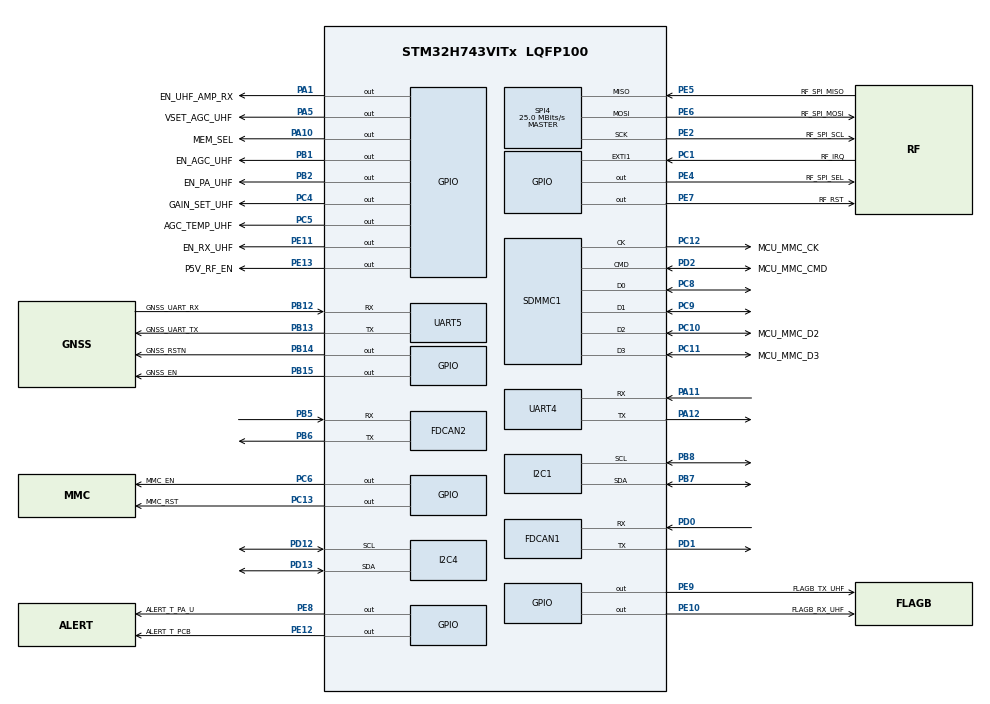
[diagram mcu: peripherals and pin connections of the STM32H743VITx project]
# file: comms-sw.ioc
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Dma.Request0=UART5_RX
Dma.Request1=UART4_TX
Dma.Request2=UART4_RX
Dma.UART4_RX.2.Direction=DMA_PERIPH_TO_MEMORY
Dma.UART4_RX.2.EventEnable=DISABLE
Dma.UART4_RX.2.FIFOMode=DMA_FIFOMODE_DISABLE
Dma.UART4_RX.2.Instance=DMA1_Stream2
Dma.UART4_RX.2.MemDataAlignment=DMA_MDATAALIGN_BYTE
Dma.UART4_RX.2.MemInc=DMA_MINC_ENABLE
Dma.UART4_RX.2.Mode=DMA_NORMAL
Dma.UART4_RX.2.PeriphDataAlignment=DMA_PDATAALIGN_BYTE
Dma.UART4_RX.2.PeriphInc=DMA_PINC_DISABLE
Dma.UART4_RX.2.Polarity=HAL_DMAMUX_REQ_GEN_RISING
Dma.UART4_RX.2.Priority=DMA_PRIORITY_LOW
Dma.UART4_RX.2.RequestNumber=1
Dma.UART4_RX.2.SignalID=NONE
Dma.UART4_RX.2.SyncEnable=DISABLE
Dma.UART4_RX.2.SyncPolarity=HAL_DMAMUX_SYNC_NO_EVENT
Dma.UART4_RX.2.SyncRequestNumber=1
Dma.UART4_RX.2.SyncSignalID=NONE
Dma.UART4_TX.1.Direction=DMA_MEMORY_TO_PERIPH
Dma.UART4_TX.1.EventEnable=DISABLE
Dma.UART4_TX.1.FIFOMode=DMA_FIFOMODE_DISABLE
Dma.UART4_TX.1.Instance=DMA1_Stream1
Dma.UART4_TX.1.MemDataAlignment=DMA_MDATAALIGN_BYTE
Dma.UART4_TX.1.MemInc=DMA_MINC_ENABLE
Dma.UART4_TX.1.Mode=DMA_NORMAL
Dma.UART4_TX.1.PeriphDataAlignment=DMA_PDATAALIGN_BYTE
Dma.UART4_TX.1.PeriphInc=DMA_PINC_DISABLE
Dma.UART4_TX.1.Polarity=HAL_DMAMUX_REQ_GEN_RISING
Dma.UART4_TX.1.Priority=DMA_PRIORITY_LOW
Dma.UART4_TX.1.RequestNumber=1
Dma.UART4_TX.1.SignalID=NONE
Dma.UART4_TX.1.SyncEnable=DISABLE
Dma.UART4_TX.1.SyncPolarity=HAL_DMAMUX_SYNC_NO_EVENT
Dma.UART4_TX.1.SyncRequestNumber=1
Dma.UART4_TX.1.SyncSignalID=NONE
Dma.UART5_RX.0.Direction=DMA_PERIPH_TO_MEMORY
Dma.UART5_RX.0.EventEnable=DISABLE
Dma.UART5_RX.0.FIFOMode=DMA_FIFOMODE_DISABLE
Dma.UART5_RX.0.Instance=DMA1_Stream0
Dma.UART5_RX.0.MemDataAlignment=DMA_MDATAALIGN_BYTE
Dma.UART5_RX.0.MemInc=DMA_MINC_ENABLE
Dma.UART5_RX.0.Mode=DMA_CIRCULAR
Dma.UART5_RX.0.PeriphDataAlignment=DMA_PDATAALIGN_BYTE
Dma.UART5_RX.0.PeriphInc=DMA_PINC_DISABLE
Dma.UART5_RX.0.Polarity=HAL_DMAMUX_REQ_GEN_RISING
Dma.UART5_RX.0.Priority=DMA_PRIORITY_LOW
Dma.UART5_RX.0.RequestNumber=1
Dma.UART5_RX.0.SignalID=NONE
Dma.UART5_RX.0.SyncEnable=DISABLE
Dma.UART5_RX.0.SyncPolarity=HAL_DMAMUX_SYNC_NO_EVENT
Dma.UART5_RX.0.SyncRequestNumber=1
Dma.UART5_RX.0.SyncSignalID=NONE
FDCAN1.CalculateBaudRateNominal=500000
FDCAN1.CalculateTimeBitNominal=2000
FDCAN1.CalculateTimeQuantumNominal=20.0
FDCAN1.DataPrescaler=25
FDCAN1.DataTimeSeg1=2
FDCAN1.ExtFiltersNbr=1
FDCAN1.NominalPrescaler=1
FDCAN1.NominalSyncJumpWidth=13
FDCAN1.NominalTimeSeg1=86
FDCAN1.NominalTimeSeg2=13
FDCAN1.RxFifo0ElmtsNbr=16
FDCAN1.StdFiltersNbr=0
FDCAN1.TxFifoQueueElmtsNbr=16
FDCAN2.CalculateBaudRateNominal=500000
FDCAN2.CalculateTimeBitNominal=2000
FDCAN2.CalculateTimeQuantumNominal=20.0
FDCAN2.DataPrescaler=25
FDCAN2.DataTimeSeg1=2
FDCAN2.ExtFiltersNbr=1
FDCAN2.MessageRAMOffset=586
FDCAN2.NominalPrescaler=1
FDCAN2.NominalSyncJumpWidth=13
FDCAN2.NominalTimeSeg1=86
FDCAN2.NominalTimeSeg2=13
FDCAN2.RxFifo0ElmtsNbr=16
FDCAN2.TxFifoQueueElmtsNbr=16
I2C1.Timing=0x00909FCE
I2C4.Timing=0x00000509
Mcu.Family=STM32H7
Mcu.Name=STM32H743VITx
Mcu.Package=LQFP100
NVIC.DMA1_Stream0_IRQn=true\:5\:0\:true\:false\:true\:false\:true\:true
NVIC.DMA1_Stream1_IRQn=true\:5\:0\:true\:false\:true\:false\:true\:true
NVIC.DMA1_Stream2_IRQn=true\:5\:0\:true\:false\:true\:false\:true\:true
NVIC.EXTI1_IRQn=true\:5\:0\:true\:false\:false\:true\:true\:true
NVIC.FDCAN1_IT0_IRQn=true\:5\:0\:true\:false\:true\:true\:true\:true
NVIC.FDCAN1_IT1_IRQn=true\:5\:0\:true\:false\:true\:true\:true\:true
NVIC.FDCAN2_IT0_IRQn=true\:5\:0\:true\:false\:true\:true\:true\:true
NVIC.FDCAN2_IT1_IRQn=true\:5\:0\:true\:false\:true\:true\:true\:true
NVIC.PriorityGroup=NVIC_PRIORITYGROUP_4
NVIC.SDMMC1_IRQn=true\:5\:0\:true\:false\:true\:true\:true\:true
NVIC.TIM1_UP_IRQn=true\:15\:0\:false\:false\:true\:false\:true\:true
NVIC.TimeBase=TIM1_UP_IRQn
NVIC.TimeBaseIP=TIM1
NVIC.UART4_IRQn=true\:5\:0\:true\:false\:true\:true\:true\:true
NVIC.UART5_IRQn=true\:5\:0\:true\:false\:true\:true\:true\:true
PA1.GPIO_Label=EN_UHF_AMP_RX
PA1.PinAttribute=Free
PA1.Signal=GPIO_Output
PA10.GPIO_Label=MEM_SEL
PA10.Signal=GPIO_Output
PA11.Mode=Asynchronous
PA11.PinAttribute=Free
PA11.Signal=UART4_RX
PA12.Mode=Asynchronous
PA12.PinAttribute=Free
PA12.Signal=UART4_TX
PA13\ (JTMS/SWDIO).Mode=Trace_Asynchronous_SW
PA13\ (JTMS/SWDIO).PinAttribute=Free
PA13\ (JTMS/SWDIO).Signal=DEBUG_JTMS-SWDIO
PA14\ (JTCK/SWCLK).Mode=Trace_Asynchronous_SW
PA14\ (JTCK/SWCLK).PinAttribute=Free
PA14\ (JTCK/SWCLK).Signal=DEBUG_JTCK-SWCLK
PA5.GPIO_Label=VSET_AGC_UHF
PA5.PinAttribute=Free
PA5.Signal=GPIO_Output
PB1.GPIO_Label=EN_AGC_UHF
PB1.PinAttribute=Free
PB1.Signal=GPIO_Output
PB12.GPIO_Label=GNSS_UART_RX
PB12.Mode=Asynchronous
PB12.Signal=UART5_RX
PB13.GPIO_Label=GNSS_UART_TX
PB13.Mode=Asynchronous
PB13.Signal=UART5_TX
PB14.GPIO_Label=GNSS_RSTN
PB14.Signal=GPIO_Output
PB15.GPIO_Label=GNSS_EN
PB15.PinState=GPIO_PIN_SET
PB15.Signal=GPIO_Output
PB2.GPIO_Label=EN_PA_UHF
PB2.PinAttribute=Free
PB2.PinState=GPIO_PIN_SET
PB2.Signal=GPIO_Output
PB3\ (JTDO/TRACESWO).Mode=Trace_Asynchronous_SW
PB3\ (JTDO/TRACESWO).PinAttribute=Free
PB3\ (JTDO/TRACESWO).Signal=DEBUG_JTDO-SWO
PB5.Mode=FDCAN_Activate
PB5.Signal=FDCAN2_RX
PB6.Mode=FDCAN_Activate
PB6.Signal=FDCAN2_TX
PB7.Mode=I2C
PB7.PinAttribute=Free
PB7.Signal=I2C1_SDA
PB8.Mode=I2C
PB8.PinAttribute=Free
PB8.Signal=I2C1_SCL
PC1.GPIO_Label=RF_IRQ
PC1.PinAttribute=Free
PC1.Signal=GPXTI1
PC10.GPIO_Label=MCU_MMC_D2
PC10.GPIO_PuPd=GPIO_PULLUP
PC10.Mode=mmc_4_bits_Wide_bus
PC10.PinAttribute=Free
PC10.Signal=SDMMC1_D2
PC11.GPIO_Label=MCU_MMC_D3
PC11.GPIO_PuPd=GPIO_PULLUP
PC11.Mode=mmc_4_bits_Wide_bus
PC11.PinAttribute=Free
PC11.Signal=SDMMC1_D3
PC12.GPIO_Label=MCU_MMC_CK
PC12.Mode=mmc_4_bits_Wide_bus
PC12.PinAttribute=Free
PC12.Signal=SDMMC1_CK
PC13.GPIO_Label=MMC_RST
PC13.PinAttribute=Free
PC13.PinState=GPIO_PIN_SET
PC13.Signal=GPIO_Output
PC14-OSC32_IN\ (OSC32_IN).Mode=LSE-External-Clock-Source
PC14-OSC32_IN\ (OSC32_IN).PinAttribute=Free
PC14-OSC32_IN\ (OSC32_IN).Signal=RCC_OSC32_IN
PC4.GPIO_Label=GAIN_SET_UHF
PC4.PinAttribute=Free
PC4.Signal=GPIO_Output
PC5.GPIO_Label=AGC_TEMP_UHF
PC5.PinAttribute=Free
PC5.Signal=GPIO_Output
PC6.GPIO_Label=MMC_EN
PC6.GPIO_Speed=GPIO_SPEED_FREQ_VERY_HIGH
PC6.PinState=GPIO_PIN_SET
PC6.Signal=GPIO_Output
PC8.GPIO_PuPd=GPIO_PULLUP
PC8.Mode=mmc_4_bits_Wide_bus
PC8.Signal=SDMMC1_D0
PC9.GPIO_PuPd=GPIO_PULLUP
PC9.Mode=mmc_4_bits_Wide_bus
PC9.Signal=SDMMC1_D1
PD0.Mode=FDCAN_Activate
PD0.Signal=FDCAN1_RX
PD1.Mode=FDCAN_Activate
PD1.Signal=FDCAN1_TX
PD12.Mode=I2C
PD12.Signal=I2C4_SCL
PD13.Mode=I2C
PD13.Signal=I2C4_SDA
PD2.GPIO_Label=MCU_MMC_CMD
PD2.GPIO_PuPd=GPIO_PULLUP
PD2.Mode=mmc_4_bits_Wide_bus
PD2.PinAttribute=Free
PD2.Signal=SDMMC1_CMD
PE10.GPIO_Label=FLAGB_RX_UHF
PE10.Signal=GPIO_Output
PE11.GPIO_Label=EN_RX_UHF
PE11.Signal=GPIO_Output
PE12.GPIO_Label=ALERT_T_PCB
PE12.Signal=GPIO_Output
PE13.GPIO_Label=P5V_RF_EN
PE13.Signal=GPIO_Output
PE2.GPIO_Label=RF_SPI_SCL
PE2.Mode=Full_Duplex_Master
PE2.PinAttribute=Free
PE2.Signal=SPI4_SCK
PE4.GPIO_Label=RF_SPI_SEL
PE4.PinAttribute=Free
PE4.Signal=GPIO_Output
PE5.GPIO_Label=RF_SPI_MISO
PE5.Mode=Full_Duplex_Master
PE5.PinAttribute=Free
PE5.Signal=SPI4_MISO
PE6.GPIO_Label=RF_SPI_MOSI
PE6.Mode=Full_Duplex_Master
PE6.PinAttribute=Free
PE6.Signal=SPI4_MOSI
PE7.GPIO_Label=RF_RST
PE7.PinAttribute=Free
PE7.PinState=GPIO_PIN_RESET
PE7.Signal=GPIO_Output
PE8.GPIO_Label=ALERT_T_PA_U
PE8.PinAttribute=Free
PE8.Signal=GPIO_Output
PE9.GPIO_Label=FLAGB_TX_UHF
PE9.Signal=GPIO_Output
PH0-OSC_IN\ (PH0).Mode=HSE-External-Clock-Source
PH0-OSC_IN\ (PH0).PinAttribute=Free
PH0-OSC_IN\ (PH0).Signal=RCC_OSC_IN
ProjectManager.HeapSize=0x200
ProjectManager.StackSize=0x400
ProjectManager.TargetToolchain=CMake
RCC.ADCFreq_Value=75000000
RCC.APB1Freq_Value=37500000
RCC.APB2Freq_Value=75000000
RCC.APB3Freq_Value=75000000
RCC.APB4Freq_Value=37500000
RCC.CortexFreq_Value=75000000
RCC.D2PPRE1=RCC_APB1_DIV2
RCC.D3PPRE=RCC_APB4_DIV2
RCC.DIVM1=1
RCC.DIVM2=1
RCC.DIVM3=1
RCC.DIVN1=12
RCC.DIVN2=12
RCC.DIVN3=12
RCC.DIVQ2=3
RCC.DIVQ3=1
RCC.DIVR3=75
RCC.FDCANCLockSelection=RCC_FDCANCLKSOURCE_PLL2
RCC.HCLKFreq_Value=75000000
RCC.HSE_VALUE=12000000
RCC.I2C4CLockSelection=RCC_I2C4CLKSOURCE_PLL3
RCC.PLL2FRACN=4096
RCC.PLL3FRACN=4096
RCC.PLLFRACN=4096
RCC.PLLSourceVirtual=RCC_PLLSOURCE_HSE
RCC.SYSCLKFreq_VALUE=75000000
RCC.SYSCLKSource=RCC_SYSCLKSOURCE_PLLCLK
RCC.Spi45ClockSelection=RCC_SPI45CLKSOURCE_PLL2
RCC.USART234578CLockSelection=RCC_USART234578CLKSOURCE_PLL2
RCC.USBFreq_Value=75000000
SDMMC1.ClockDiv=1
SDMMC1.ClockPowerSave=SDMMC_CLOCK_POWER_SAVE_ENABLE
SDMMC1.HardwareFlowControl=SDMMC_HARDWARE_FLOW_CONTROL_ENABLE
SPI4.CalculateBaudRate=25.0 MBits/s
SPI4.DataSize=SPI_DATASIZE_8BIT
SPI4.Direction=SPI_DIRECTION_2LINES
SPI4.Mode=SPI_MODE_MASTER
SPI4.VirtualType=VM_MASTER
UART5.SwapParam=UART_ADVFEATURE_SWAP_ENABLE
VP_CRC_VS_CRC.Mode=CRC_Activate
VP_SYS_VS_tim1.Mode=TIM1
board=custom

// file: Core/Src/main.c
/* USER CODE BEGIN Header */
/**
  ******************************************************************************
  * @file           : main.c
  * @brief          : Main program body
  ******************************************************************************
  * @attention
  *
  * Copyright (c) 2024 STMicroelectronics.
  * All rights reserved.
  *
  * This software is licensed under terms that can be found in the LICENSE file
  * in the root directory of this software component.
  * If no LICENSE file comes with this software, it is provided AS-IS.
  *
  ******************************************************************************
  */
/* USER CODE END Header */
#include "main.h"

CRC_HandleTypeDef hcrc;

FDCAN_HandleTypeDef hfdcan1;
FDCAN_HandleTypeDef hfdcan2;

I2C_HandleTypeDef hi2c1;
I2C_HandleTypeDef hi2c4;

MMC_HandleTypeDef hmmc1;

SPI_HandleTypeDef hspi4;

UART_HandleTypeDef huart4;
UART_HandleTypeDef huart5;
DMA_HandleTypeDef hdma_uart4_tx;
DMA_HandleTypeDef hdma_uart4_rx;
DMA_HandleTypeDef hdma_uart5_rx;

void SystemClock_Config(void);
void PeriphCommonClock_Config(void);
static void MX_GPIO_Init(void);
static void MX_DMA_Init(void);
static void MX_SPI4_Init(void);
static void MX_UART4_Init(void);
static void MX_I2C4_Init(void);
static void MX_I2C1_Init(void);
static void MX_UART5_Init(void);
static void MX_SDMMC1_MMC_Init(void);
static void MX_FDCAN1_Init(void);
static void MX_FDCAN2_Init(void);
static void MX_CRC_Init(void);

/* USER CODE BEGIN 0 */
void app_main(void);
/* USER CODE END 0 */

int main(void)
{

  /* MCU Configuration--------------------------------------------------------*/

  /* Reset of all peripherals, Initializes the Flash interface and the Systick. */
  HAL_Init();

  /* USER CODE BEGIN Init */
    HAL_Delay(1000);
  /* USER CODE END Init */

  /* Configure the system clock */
  SystemClock_Config();

/* Configure the peripherals common clocks */
  PeriphCommonClock_Config();

  /* Initialize all configured peripherals */
  MX_GPIO_Init();
  MX_DMA_Init();
  MX_SPI4_Init();
  MX_UART4_Init();
  MX_I2C4_Init();
  MX_I2C1_Init();
  MX_UART5_Init();
  MX_SDMMC1_MMC_Init();
  MX_FDCAN1_Init();
  MX_FDCAN2_Init();
  MX_CRC_Init();
  /* USER CODE BEGIN 2 */
    app_main();
  /* USER CODE END 2 */

  /* Infinite loop */
  while (1)
  {

  }
}

void SystemClock_Config(void)
{
  RCC_OscInitTypeDef RCC_OscInitStruct = {0};
  RCC_ClkInitTypeDef RCC_ClkInitStruct = {0};

  /** Supply configuration update enable
  */
  HAL_PWREx_ConfigSupply(PWR_LDO_SUPPLY);

  /** Configure the main internal regulator output voltage
  */
  __HAL_PWR_VOLTAGESCALING_CONFIG(PWR_REGULATOR_VOLTAGE_SCALE3);

  while(!__HAL_PWR_GET_FLAG(PWR_FLAG_VOSRDY)) {}

  /** Initializes the RCC Oscillators according to the specified parameters
  * in the RCC_OscInitTypeDef structure.
  */
  RCC_OscInitStruct.OscillatorType = RCC_OSCILLATORTYPE_HSE;
  RCC_OscInitStruct.HSEState = RCC_HSE_BYPASS;
  RCC_OscInitStruct.PLL.PLLState = RCC_PLL_ON;
  RCC_OscInitStruct.PLL.PLLSource = RCC_PLLSOURCE_HSE;
  RCC_OscInitStruct.PLL.PLLM = 1;
  RCC_OscInitStruct.PLL.PLLN = 12;
  RCC_OscInitStruct.PLL.PLLP = 2;
  RCC_OscInitStruct.PLL.PLLQ = 2;
  RCC_OscInitStruct.PLL.PLLR = 2;
  RCC_OscInitStruct.PLL.PLLRGE = RCC_PLL1VCIRANGE_3;
  RCC_OscInitStruct.PLL.PLLVCOSEL = RCC_PLL1VCOMEDIUM;
  RCC_OscInitStruct.PLL.PLLFRACN = 4096;
  if (HAL_RCC_OscConfig(&RCC_OscInitStruct) != HAL_OK)
  {
    Error_Handler();
  }

  /** Initializes the CPU, AHB and APB buses clocks
  */
  RCC_ClkInitStruct.ClockType = RCC_CLOCKTYPE_HCLK|RCC_CLOCKTYPE_SYSCLK
                              |RCC_CLOCKTYPE_PCLK1|RCC_CLOCKTYPE_PCLK2
                              |RCC_CLOCKTYPE_D3PCLK1|RCC_CLOCKTYPE_D1PCLK1;
  RCC_ClkInitStruct.SYSCLKSource = RCC_SYSCLKSOURCE_PLLCLK;
  RCC_ClkInitStruct.SYSCLKDivider = RCC_SYSCLK_DIV1;
  RCC_ClkInitStruct.AHBCLKDivider = RCC_HCLK_DIV1;
  RCC_ClkInitStruct.APB3CLKDivider = RCC_APB3_DIV1;
  RCC_ClkInitStruct.APB1CLKDivider = RCC_APB1_DIV2;
  RCC_ClkInitStruct.APB2CLKDivider = RCC_APB2_DIV1;
  RCC_ClkInitStruct.APB4CLKDivider = RCC_APB4_DIV2;

  if (HAL_RCC_ClockConfig(&RCC_ClkInitStruct, FLASH_LATENCY_1) != HAL_OK)
  {
    Error_Handler();
  }
}

void PeriphCommonClock_Config(void)
{
  RCC_PeriphCLKInitTypeDef PeriphClkInitStruct = {0};

  /** Initializes the peripherals clock
  */
  PeriphClkInitStruct.PeriphClockSelection = RCC_PERIPHCLK_SPI4|RCC_PERIPHCLK_UART5
                              |RCC_PERIPHCLK_FDCAN|RCC_PERIPHCLK_UART4;
  PeriphClkInitStruct.PLL2.PLL2M = 1;
  PeriphClkInitStruct.PLL2.PLL2N = 12;
  PeriphClkInitStruct.PLL2.PLL2P = 2;
  PeriphClkInitStruct.PLL2.PLL2Q = 3;
  PeriphClkInitStruct.PLL2.PLL2R = 2;
  PeriphClkInitStruct.PLL2.PLL2RGE = RCC_PLL2VCIRANGE_3;
  PeriphClkInitStruct.PLL2.PLL2VCOSEL = RCC_PLL2VCOMEDIUM;
  PeriphClkInitStruct.PLL2.PLL2FRACN = 4096;
  PeriphClkInitStruct.Spi45ClockSelection = RCC_SPI45CLKSOURCE_PLL2;
  PeriphClkInitStruct.FdcanClockSelection = RCC_FDCANCLKSOURCE_PLL2;
  PeriphClkInitStruct.Usart234578ClockSelection = RCC_USART234578CLKSOURCE_PLL2;
  if (HAL_RCCEx_PeriphCLKConfig(&PeriphClkInitStruct) != HAL_OK)
  {
    Error_Handler();
  }
}

static void MX_CRC_Init(void)
{

  hcrc.Instance = CRC;
  hcrc.Init.DefaultPolynomialUse = DEFAULT_POLYNOMIAL_ENABLE;
  hcrc.Init.DefaultInitValueUse = DEFAULT_INIT_VALUE_ENABLE;
  hcrc.Init.InputDataInversionMode = CRC_INPUTDATA_INVERSION_NONE;
  hcrc.Init.OutputDataInversionMode = CRC_OUTPUTDATA_INVERSION_DISABLE;
  hcrc.InputDataFormat = CRC_INPUTDATA_FORMAT_BYTES;
  if (HAL_CRC_Init(&hcrc) != HAL_OK)
  {
    Error_Handler();
  }

}

static void MX_FDCAN1_Init(void)
{

  hfdcan1.Instance = FDCAN1;
  hfdcan1.Init.FrameFormat = FDCAN_FRAME_CLASSIC;
  hfdcan1.Init.Mode = FDCAN_MODE_NORMAL;
  hfdcan1.Init.AutoRetransmission = DISABLE;
  hfdcan1.Init.TransmitPause = DISABLE;
  hfdcan1.Init.ProtocolException = DISABLE;
  hfdcan1.Init.NominalPrescaler = 1;
  hfdcan1.Init.NominalSyncJumpWidth = 13;
  hfdcan1.Init.NominalTimeSeg1 = 86;
  hfdcan1.Init.NominalTimeSeg2 = 13;
  hfdcan1.Init.DataPrescaler = 25;
  hfdcan1.Init.DataSyncJumpWidth = 1;
  hfdcan1.Init.DataTimeSeg1 = 2;
  hfdcan1.Init.DataTimeSeg2 = 1;
  hfdcan1.Init.MessageRAMOffset = 0;
  hfdcan1.Init.StdFiltersNbr = 0;
  hfdcan1.Init.ExtFiltersNbr = 1;
  hfdcan1.Init.RxFifo0ElmtsNbr = 16;
  hfdcan1.Init.RxFifo0ElmtSize = FDCAN_DATA_BYTES_8;
  hfdcan1.Init.RxFifo1ElmtsNbr = 0;
  hfdcan1.Init.RxFifo1ElmtSize = FDCAN_DATA_BYTES_8;
  hfdcan1.Init.RxBuffersNbr = 0;
  hfdcan1.Init.RxBufferSize = FDCAN_DATA_BYTES_8;
  hfdcan1.Init.TxEventsNbr = 0;
  hfdcan1.Init.TxBuffersNbr = 0;
  hfdcan1.Init.TxFifoQueueElmtsNbr = 16;
  hfdcan1.Init.TxFifoQueueMode = FDCAN_TX_FIFO_OPERATION;
  hfdcan1.Init.TxElmtSize = FDCAN_DATA_BYTES_8;
  if (HAL_FDCAN_Init(&hfdcan1) != HAL_OK)
  {
    Error_Handler();
  }

}

static void MX_FDCAN2_Init(void)
{

  hfdcan2.Instance = FDCAN2;
  hfdcan2.Init.FrameFormat = FDCAN_FRAME_CLASSIC;
  hfdcan2.Init.Mode = FDCAN_MODE_NORMAL;
  hfdcan2.Init.AutoRetransmission = DISABLE;
  hfdcan2.Init.TransmitPause = DISABLE;
  hfdcan2.Init.ProtocolException = DISABLE;
  hfdcan2.Init.NominalPrescaler = 1;
  hfdcan2.Init.NominalSyncJumpWidth = 13;
  hfdcan2.Init.NominalTimeSeg1 = 86;
  hfdcan2.Init.NominalTimeSeg2 = 13;
  hfdcan2.Init.DataPrescaler = 25;
  hfdcan2.Init.DataSyncJumpWidth = 1;
  hfdcan2.Init.DataTimeSeg1 = 2;
  hfdcan2.Init.DataTimeSeg2 = 1;
  hfdcan2.Init.MessageRAMOffset = 586;
  hfdcan2.Init.StdFiltersNbr = 0;
  hfdcan2.Init.ExtFiltersNbr = 1;
  hfdcan2.Init.RxFifo0ElmtsNbr = 16;
  hfdcan2.Init.RxFifo0ElmtSize = FDCAN_DATA_BYTES_8;
  hfdcan2.Init.RxFifo1ElmtsNbr = 0;
  hfdcan2.Init.RxFifo1ElmtSize = FDCAN_DATA_BYTES_8;
  hfdcan2.Init.RxBuffersNbr = 0;
  hfdcan2.Init.RxBufferSize = FDCAN_DATA_BYTES_8;
  hfdcan2.Init.TxEventsNbr = 0;
  hfdcan2.Init.TxBuffersNbr = 0;
  hfdcan2.Init.TxFifoQueueElmtsNbr = 16;
  hfdcan2.Init.TxFifoQueueMode = FDCAN_TX_FIFO_OPERATION;
  hfdcan2.Init.TxElmtSize = FDCAN_DATA_BYTES_8;
  if (HAL_FDCAN_Init(&hfdcan2) != HAL_OK)
  {
    Error_Handler();
  }

}

static void MX_I2C1_Init(void)
{

  hi2c1.Instance = I2C1;
  hi2c1.Init.Timing = 0x00909FCE;
  hi2c1.Init.OwnAddress1 = 0;
  hi2c1.Init.AddressingMode = I2C_ADDRESSINGMODE_7BIT;
  hi2c1.Init.DualAddressMode = I2C_DUALADDRESS_DISABLE;
  hi2c1.Init.OwnAddress2 = 0;
  hi2c1.Init.OwnAddress2Masks = I2C_OA2_NOMASK;
  hi2c1.Init.GeneralCallMode = I2C_GENERALCALL_DISABLE;
  hi2c1.Init.NoStretchMode = I2C_NOSTRETCH_DISABLE;
  if (HAL_I2C_Init(&hi2c1) != HAL_OK)
  {
    Error_Handler();
  }

  /** Configure Analogue filter
  */
  if (HAL_I2CEx_ConfigAnalogFilter(&hi2c1, I2C_ANALOGFILTER_ENABLE) != HAL_OK)
  {
    Error_Handler();
  }

  /** Configure Digital filter
  */
  if (HAL_I2CEx_ConfigDigitalFilter(&hi2c1, 0) != HAL_OK)
  {
    Error_Handler();
  }

}

static void MX_I2C4_Init(void)
{

  hi2c4.Instance = I2C4;
  hi2c4.Init.Timing = 0x00000509;
  hi2c4.Init.OwnAddress1 = 0;
  hi2c4.Init.AddressingMode = I2C_ADDRESSINGMODE_7BIT;
  hi2c4.Init.DualAddressMode = I2C_DUALADDRESS_DISABLE;
  hi2c4.Init.OwnAddress2 = 0;
  hi2c4.Init.OwnAddress2Masks = I2C_OA2_NOMASK;
  hi2c4.Init.GeneralCallMode = I2C_GENERALCALL_DISABLE;
  hi2c4.Init.NoStretchMode = I2C_NOSTRETCH_DISABLE;
  if (HAL_I2C_Init(&hi2c4) != HAL_OK)
  {
    Error_Handler();
  }

  /** Configure Analogue filter
  */
  if (HAL_I2CEx_ConfigAnalogFilter(&hi2c4, I2C_ANALOGFILTER_ENABLE) != HAL_OK)
  {
    Error_Handler();
  }

  /** Configure Digital filter
  */
  if (HAL_I2CEx_ConfigDigitalFilter(&hi2c4, 0) != HAL_OK)
  {
    Error_Handler();
  }

}

static void MX_SDMMC1_MMC_Init(void)
{

  /* USER CODE BEGIN SDMMC1_Init 0 */
    HAL_GPIO_WritePin(MMC_EN_GPIO_Port, MMC_EN_Pin, ((GPIO_PinState) RESET));
    HAL_Delay(1500);
    HAL_GPIO_WritePin(MEM_SEL_GPIO_Port, MEM_SEL_Pin, ((GPIO_PinState) SET));
    HAL_Delay(1500);
    HAL_GPIO_WritePin(MMC_RST_GPIO_Port, MMC_RST_Pin, ((GPIO_PinState) RESET));
    HAL_Delay(1500);
  /* USER CODE END SDMMC1_Init 0 */

  hmmc1.Instance = SDMMC1;
  hmmc1.Init.ClockEdge = SDMMC_CLOCK_EDGE_RISING;
  hmmc1.Init.ClockPowerSave = SDMMC_CLOCK_POWER_SAVE_ENABLE;
  hmmc1.Init.BusWide = SDMMC_BUS_WIDE_4B;
  hmmc1.Init.HardwareFlowControl = SDMMC_HARDWARE_FLOW_CONTROL_ENABLE;
  hmmc1.Init.ClockDiv = 1;
  if (HAL_MMC_Init(&hmmc1) != HAL_OK)
  {
    Error_Handler();
  }

}

static void MX_SPI4_Init(void)
{

  /* SPI4 parameter configuration*/
  hspi4.Instance = SPI4;
  hspi4.Init.Mode = SPI_MODE_MASTER;
  hspi4.Init.Direction = SPI_DIRECTION_2LINES;
  hspi4.Init.DataSize = SPI_DATASIZE_8BIT;
  hspi4.Init.CLKPolarity = SPI_POLARITY_LOW;
  hspi4.Init.CLKPhase = SPI_PHASE_1EDGE;
  hspi4.Init.NSS = SPI_NSS_SOFT;
  hspi4.Init.BaudRatePrescaler = SPI_BAUDRATEPRESCALER_2;
  hspi4.Init.FirstBit = SPI_FIRSTBIT_MSB;
  hspi4.Init.TIMode = SPI_TIMODE_DISABLE;
  hspi4.Init.CRCCalculation = SPI_CRCCALCULATION_DISABLE;
  hspi4.Init.CRCPolynomial = 0x0;
  hspi4.Init.NSSPMode = SPI_NSS_PULSE_ENABLE;
  hspi4.Init.NSSPolarity = SPI_NSS_POLARITY_LOW;
  hspi4.Init.FifoThreshold = SPI_FIFO_THRESHOLD_01DATA;
  hspi4.Init.TxCRCInitializationPattern = SPI_CRC_INITIALIZATION_ALL_ZERO_PATTERN;
  hspi4.Init.RxCRCInitializationPattern = SPI_CRC_INITIALIZATION_ALL_ZERO_PATTERN;
  hspi4.Init.MasterSSIdleness = SPI_MASTER_SS_IDLENESS_00CYCLE;
  hspi4.Init.MasterInterDataIdleness = SPI_MASTER_INTERDATA_IDLENESS_00CYCLE;
  hspi4.Init.MasterReceiverAutoSusp = SPI_MASTER_RX_AUTOSUSP_DISABLE;
  hspi4.Init.MasterKeepIOState = SPI_MASTER_KEEP_IO_STATE_DISABLE;
  hspi4.Init.IOSwap = SPI_IO_SWAP_DISABLE;
  if (HAL_SPI_Init(&hspi4) != HAL_OK)
  {
    Error_Handler();
  }

}

static void MX_UART4_Init(void)
{

  huart4.Instance = UART4;
  huart4.Init.BaudRate = 115200;
  huart4.Init.WordLength = UART_WORDLENGTH_8B;
  huart4.Init.StopBits = UART_STOPBITS_1;
  huart4.Init.Parity = UART_PARITY_NONE;
  huart4.Init.Mode = UART_MODE_TX_RX;
  huart4.Init.HwFlowCtl = UART_HWCONTROL_NONE;
  huart4.Init.OverSampling = UART_OVERSAMPLING_16;
  huart4.Init.OneBitSampling = UART_ONE_BIT_SAMPLE_DISABLE;
  huart4.Init.ClockPrescaler = UART_PRESCALER_DIV1;
  huart4.AdvancedInit.AdvFeatureInit = UART_ADVFEATURE_NO_INIT;
  if (HAL_UART_Init(&huart4) != HAL_OK)
  {
    Error_Handler();
  }
  if (HAL_UARTEx_SetTxFifoThreshold(&huart4, UART_TXFIFO_THRESHOLD_1_8) != HAL_OK)
  {
    Error_Handler();
  }
  if (HAL_UARTEx_SetRxFifoThreshold(&huart4, UART_RXFIFO_THRESHOLD_1_8) != HAL_OK)
  {
    Error_Handler();
  }
  if (HAL_UARTEx_DisableFifoMode(&huart4) != HAL_OK)
  {
    Error_Handler();
  }

}

static void MX_UART5_Init(void)
{

  huart5.Instance = UART5;
  huart5.Init.BaudRate = 115200;
  huart5.Init.WordLength = UART_WORDLENGTH_8B;
  huart5.Init.StopBits = UART_STOPBITS_1;
  huart5.Init.Parity = UART_PARITY_NONE;
  huart5.Init.Mode = UART_MODE_TX_RX;
  huart5.Init.HwFlowCtl = UART_HWCONTROL_NONE;
  huart5.Init.OverSampling = UART_OVERSAMPLING_16;
  huart5.Init.OneBitSampling = UART_ONE_BIT_SAMPLE_DISABLE;
  huart5.Init.ClockPrescaler = UART_PRESCALER_DIV1;
  huart5.AdvancedInit.AdvFeatureInit = UART_ADVFEATURE_SWAP_INIT;
  huart5.AdvancedInit.Swap = UART_ADVFEATURE_SWAP_ENABLE;
  if (HAL_UART_Init(&huart5) != HAL_OK)
  {
    Error_Handler();
  }
  if (HAL_UARTEx_SetTxFifoThreshold(&huart5, UART_TXFIFO_THRESHOLD_1_8) != HAL_OK)
  {
    Error_Handler();
  }
  if (HAL_UARTEx_SetRxFifoThreshold(&huart5, UART_RXFIFO_THRESHOLD_1_8) != HAL_OK)
  {
    Error_Handler();
  }
  if (HAL_UARTEx_DisableFifoMode(&huart5) != HAL_OK)
  {
    Error_Handler();
  }

}

static void MX_DMA_Init(void)
{

  /* DMA controller clock enable */
  __HAL_RCC_DMA1_CLK_ENABLE();

  /* DMA interrupt init */
  /* DMA1_Stream0_IRQn interrupt configuration */
  HAL_NVIC_SetPriority(DMA1_Stream0_IRQn, 5, 0);
  HAL_NVIC_EnableIRQ(DMA1_Stream0_IRQn);
  /* DMA1_Stream1_IRQn interrupt configuration */
  HAL_NVIC_SetPriority(DMA1_Stream1_IRQn, 5, 0);
  HAL_NVIC_EnableIRQ(DMA1_Stream1_IRQn);
  /* DMA1_Stream2_IRQn interrupt configuration */
  HAL_NVIC_SetPriority(DMA1_Stream2_IRQn, 5, 0);
  HAL_NVIC_EnableIRQ(DMA1_Stream2_IRQn);

}

static void MX_GPIO_Init(void)
{
  GPIO_InitTypeDef GPIO_InitStruct = {0};

  /* GPIO Ports Clock Enable */
  __HAL_RCC_GPIOE_CLK_ENABLE();
  __HAL_RCC_GPIOC_CLK_ENABLE();
  __HAL_RCC_GPIOH_CLK_ENABLE();
  __HAL_RCC_GPIOA_CLK_ENABLE();
  __HAL_RCC_GPIOB_CLK_ENABLE();
  __HAL_RCC_GPIOD_CLK_ENABLE();

  /*Configure GPIO pin Output Level */
  HAL_GPIO_WritePin(GPIOE, RF_SPI_SEL_Pin|RF_RST_Pin|ALERT_T_PA_U_Pin|FLAGB_TX_UHF_Pin
                          |FLAGB_RX_UHF_Pin|EN_RX_UHF_Pin|ALERT_T_PCB_Pin|P5V_RF_EN_Pin, GPIO_PIN_RESET);

  /*Configure GPIO pin Output Level */
  HAL_GPIO_WritePin(GPIOC, MMC_RST_Pin|MMC_EN_Pin, GPIO_PIN_SET);

  /*Configure GPIO pin Output Level */
  HAL_GPIO_WritePin(GPIOA, EN_UHF_AMP_RX_Pin|VSET_AGC_UHF_Pin|MEM_SEL_Pin, GPIO_PIN_RESET);

  /*Configure GPIO pin Output Level */
  HAL_GPIO_WritePin(GPIOC, GAIN_SET_UHF_Pin|AGC_TEMP_UHF_Pin, GPIO_PIN_RESET);

  /*Configure GPIO pin Output Level */
  HAL_GPIO_WritePin(GPIOB, EN_AGC_UHF_Pin|GNSS_RSTN_Pin, GPIO_PIN_RESET);

  /*Configure GPIO pin Output Level */
  HAL_GPIO_WritePin(GPIOB, EN_PA_UHF_Pin|GNSS_EN_Pin, GPIO_PIN_SET);

  /*Configure GPIO pins : RF_SPI_SEL_Pin RF_RST_Pin ALERT_T_PA_U_Pin FLAGB_TX_UHF_Pin
                           FLAGB_RX_UHF_Pin EN_RX_UHF_Pin ALERT_T_PCB_Pin P5V_RF_EN_Pin */
  GPIO_InitStruct.Pin = RF_SPI_SEL_Pin|RF_RST_Pin|ALERT_T_PA_U_Pin|FLAGB_TX_UHF_Pin
                          |FLAGB_RX_UHF_Pin|EN_RX_UHF_Pin|ALERT_T_PCB_Pin|P5V_RF_EN_Pin;
  GPIO_InitStruct.Mode = GPIO_MODE_OUTPUT_PP;
  GPIO_InitStruct.Pull = GPIO_NOPULL;
  GPIO_InitStruct.Speed = GPIO_SPEED_FREQ_LOW;
  HAL_GPIO_Init(GPIOE, &GPIO_InitStruct);

  /*Configure GPIO pins : MMC_RST_Pin GAIN_SET_UHF_Pin AGC_TEMP_UHF_Pin */
  GPIO_InitStruct.Pin = MMC_RST_Pin|GAIN_SET_UHF_Pin|AGC_TEMP_UHF_Pin;
  GPIO_InitStruct.Mode = GPIO_MODE_OUTPUT_PP;
  GPIO_InitStruct.Pull = GPIO_NOPULL;
  GPIO_InitStruct.Speed = GPIO_SPEED_FREQ_LOW;
  HAL_GPIO_Init(GPIOC, &GPIO_InitStruct);

  /*Configure GPIO pin : RF_IRQ_Pin */
  GPIO_InitStruct.Pin = RF_IRQ_Pin;
  GPIO_InitStruct.Mode = GPIO_MODE_IT_RISING;
  GPIO_InitStruct.Pull = GPIO_NOPULL;
  HAL_GPIO_Init(RF_IRQ_GPIO_Port, &GPIO_InitStruct);

  /*Configure GPIO pins : EN_UHF_AMP_RX_Pin VSET_AGC_UHF_Pin MEM_SEL_Pin */
  GPIO_InitStruct.Pin = EN_UHF_AMP_RX_Pin|VSET_AGC_UHF_Pin|MEM_SEL_Pin;
  GPIO_InitStruct.Mode = GPIO_MODE_OUTPUT_PP;
  GPIO_InitStruct.Pull = GPIO_NOPULL;
  GPIO_InitStruct.Speed = GPIO_SPEED_FREQ_LOW;
  HAL_GPIO_Init(GPIOA, &GPIO_InitStruct);

  /*Configure GPIO pins : EN_AGC_UHF_Pin EN_PA_UHF_Pin GNSS_RSTN_Pin GNSS_EN_Pin */
  GPIO_InitStruct.Pin = EN_AGC_UHF_Pin|EN_PA_UHF_Pin|GNSS_RSTN_Pin|GNSS_EN_Pin;
  GPIO_InitStruct.Mode = GPIO_MODE_OUTPUT_PP;
  GPIO_InitStruct.Pull = GPIO_NOPULL;
  GPIO_InitStruct.Speed = GPIO_SPEED_FREQ_LOW;
  HAL_GPIO_Init(GPIOB, &GPIO_InitStruct);

  /*Configure GPIO pin : MMC_EN_Pin */
  GPIO_InitStruct.Pin = MMC_EN_Pin;
  GPIO_InitStruct.Mode = GPIO_MODE_OUTPUT_PP;
  GPIO_InitStruct.Pull = GPIO_NOPULL;
  GPIO_InitStruct.Speed = GPIO_SPEED_FREQ_VERY_HIGH;
  HAL_GPIO_Init(MMC_EN_GPIO_Port, &GPIO_InitStruct);

  /* EXTI interrupt init*/
  HAL_NVIC_SetPriority(EXTI1_IRQn, 5, 0);
  HAL_NVIC_EnableIRQ(EXTI1_IRQn);

/* USER CODE BEGIN MX_GPIO_Init_2 */
  HAL_NVIC_DisableIRQ(EXTI1_IRQn);
/* USER CODE END MX_GPIO_Init_2 */
}

void HAL_TIM_PeriodElapsedCallback(TIM_HandleTypeDef *htim)
{
  if (htim->Instance == TIM1) {
    HAL_IncTick();
  }
}

void Error_Handler(void)
{
  __disable_irq();
  while (1)
  {
  }
}
